# CH32F203xx register map
Vendor: WCH Ltd.; File version: 1.0
Registers are 32-bit, read-write, reset 0x0 unless marked. A register's access mark holds for its fields unless they carry their own. Offsets are from the block's base; [hi:lo] are bit positions; {n}, {i} and the like mark numbered series.

## AFIO — Alternate function I/O
Base 0x40010000
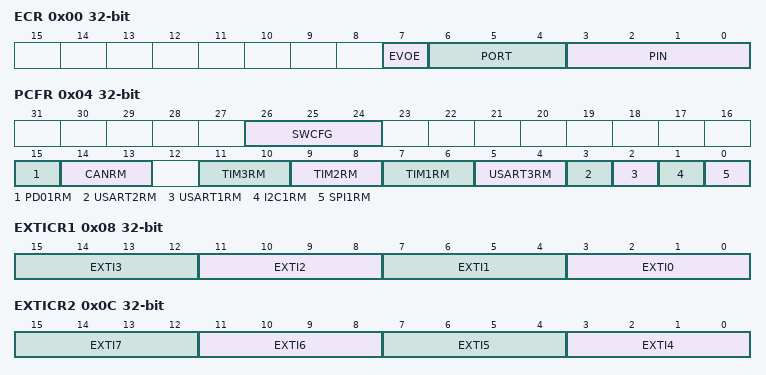
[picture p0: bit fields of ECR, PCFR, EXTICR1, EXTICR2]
0x00 ECR — Event Control Register (AFIO_ECR)
  [7] EVOE — Event Output Enable
  [6:4] PORT — Port selection
  [3:0] PIN — Pin selection
0x04 PCFR access per field — AF remap and debug I/O configuration register (AFIO_PCFR)
  [26:24] SWCFG wo — Serial wire JTAG configuration
  [15] PD01RM rw — Port D0/Port D1 mapping on OSCIN/OSCOUT
  [14:13] CANRM rw — CAN1 remapping
  [11:10] TIM3RM rw — TIM3 remapping
  [9:8] TIM2RM rw — TIM2 remapping
  [7:6] TIM1RM rw — TIM1 remapping
  [5:4] USART3RM rw — USART3 remapping
  [3] USART2RM rw — USART2 remapping
  [2] USART1RM rw — USART1 remapping
  [1] I2C1RM rw — I2C1 remapping
  [0] SPI1RM rw — SPI1 remapping
0x08 EXTICR1 — External interrupt configuration register 1 (AFIO_EXTICR1)
  [4n+3:4n] EXTI{n} (n=0..3) — EXTI{n} configuration
0x0C EXTICR2 — External interrupt configuration register 2 (AFIO_EXTICR2)
  [4n-13:4n-16] EXTI{n} (n=4..7) — EXTI{n} configuration
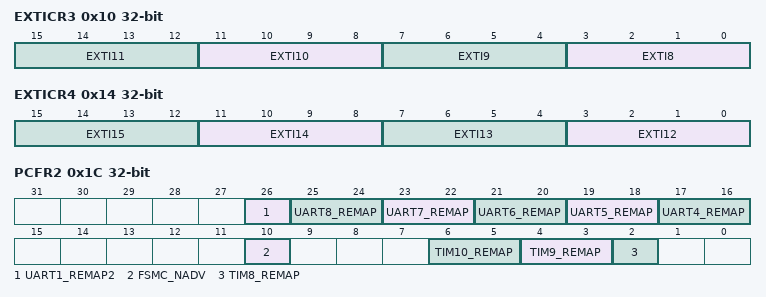
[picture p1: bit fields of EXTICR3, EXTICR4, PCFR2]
0x10 EXTICR3 — External interrupt configuration register 3 (AFIO_EXTICR3)
  [4n-29:4n-32] EXTI{n} (n=8..11) — EXTI{n} configuration
0x14 EXTICR4 — External interrupt configuration register 4 (AFIO_EXTICR4)
  [4n-45:4n-48] EXTI{n} (n=12..15) — EXTI{n} configuration
0x1C PCFR2 — AF remap and debug I/O configuration register (AFIO_PCFR2)
  [26] UART1_REMAP2 — UART1 remapping
  [2n+9:2n+8] UART{n}_REMAP (n=4..8) — UART{n} remapping
  [10] FSMC_NADV
  [6:5] TIM10_REMAP — TIM10 remapping
  [4:3] TIM9_REMAP — TIM9 remapping
  [2] TIM8_REMAP — TIM8 remapping

## EXTI
Base 0x40010400
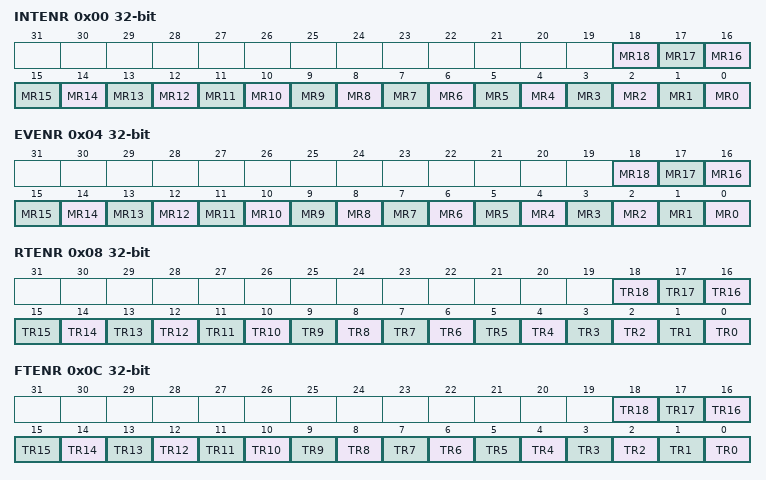
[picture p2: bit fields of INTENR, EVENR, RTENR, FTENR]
0x00 INTENR — Interrupt mask register (EXTI_INTENR)
  [n] MR{n} (n=0..18) — Interrupt Mask on line {n}
0x04 EVENR — Event mask register (EXTI_EVENR)
  [n] MR{n} (n=0..18) — Event Mask on line {n}
0x08 RTENR — Rising Trigger selection register (EXTI_RTENR)
  [n] TR{n} (n=0..18) — Rising trigger event configuration of line {n}
0x0C FTENR — Falling Trigger selection register (EXTI_FTENR)
  [n] TR{n} (n=0..18) — Falling trigger event configuration of line {n}
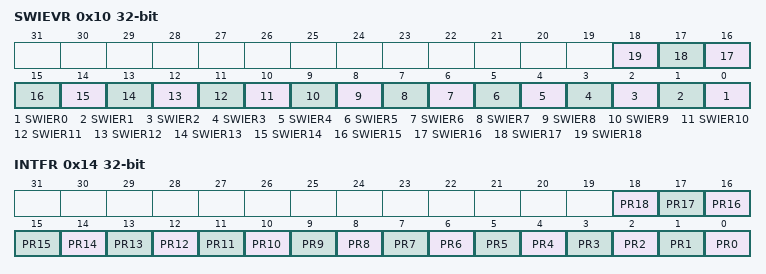
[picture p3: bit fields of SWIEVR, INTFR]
0x10 SWIEVR — Software interrupt event register (EXTI_SWIEVR)
  [n] SWIER{n} (n=0..18) — Software Interrupt on line {n}
0x14 INTFR — Pending register (EXTI_INTFR)
  [n] PR{n} (n=0..18) — Pending bit {n}

## RTC — Real time clock
Base 0x40002800
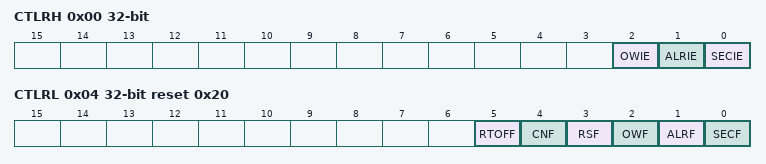
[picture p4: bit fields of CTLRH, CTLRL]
0x00 CTLRH — RTC Control Register High
  [2] OWIE — Overflow interrupt Enable
  [1] ALRIE — Alarm interrupt Enable
  [0] SECIE — Second interrupt Enable
0x04 CTLRL access per field reset 0x20 — RTC Control Register Low
  [5] RTOFF ro — RTC operation OFF
  [4] CNF rw — Configuration Flag
  [3] RSF rw — Registers Synchronized Flag
  [2] OWF rw — Overflow Flag
  [1] ALRF rw — Alarm Flag
  [0] SECF rw — Second Flag
0x08 PSCRH wo — RTC Prescaler Load Register High
  [3:0] PRLH
0x0C PSCRL wo reset 0x8000 — RTC Prescaler Load Register Low
  [15:0] PRLL — RTC Prescaler Divider Register Low
0x10 DIVH ro — RTC Prescaler Divider Register High
  [3:0] DIVH — RTC prescaler divider register high
0x14 DIVL ro reset 0x8000 — RTC Prescaler Divider Register Low
  [15:0] DIVL — RTC prescaler divider register Low
0x18 CNTH — RTC Counter Register High
  [15:0] CNTH — RTC counter register high
0x1C CNTL — RTC Counter Register Low
  [15:0] CNTL — RTC counter register Low
0x20 ALRMH wo reset 0xFFFF — RTC Alarm Register High
  [15:0] ALRH — RTC alarm register high
0x24 ALRML wo reset 0xFFFF — RTC Alarm Register Low
  [15:0] ALRL — RTC alarm register low

## BKP — Backup registers
Base 0x40006C00
0x00 DATAR1 — Backup data register (BKP_DR)
  [15:0] D1 — Backup data
0x04 DATAR2 — Backup data register (BKP_DR)
  [15:0] D2 — Backup data
0x08 DATAR3 — Backup data register (BKP_DR)
  [15:0] D3 — Backup data
0x0C DATAR4 — Backup data register (BKP_DR)
  [15:0] D4 — Backup data
0x10 DATAR5 — Backup data register (BKP_DR)
  [15:0] D5 — Backup data
0x14 DATAR6 — Backup data register (BKP_DR)
  [15:0] D6 — Backup data
0x18 DATAR7 — Backup data register (BKP_DR)
  [15:0] D7 — Backup data
0x1C DATAR8 — Backup data register (BKP_DR)
  [15:0] D8 — Backup data
0x20 DATAR9 — Backup data register (BKP_DR)
  [15:0] D9 — Backup data
0x24 DATAR10 — Backup data register (BKP_DR)
  [15:0] D10 — Backup data
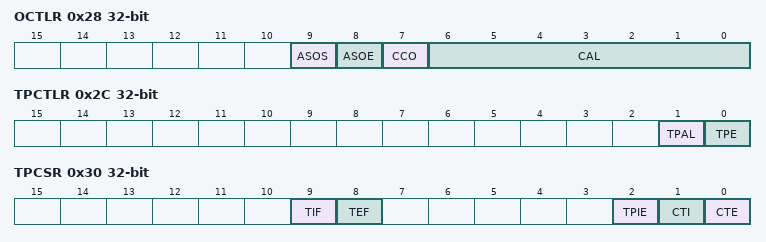
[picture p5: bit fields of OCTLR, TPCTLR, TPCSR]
0x28 OCTLR — RTC clock calibration register (BKP_OCTLR)
  [9] ASOS — Alarm or second output selection
  [8] ASOE — Alarm or second output enable
  [7] CCO — Calibration Clock Output
  [6:0] CAL — Calibration value
0x2C TPCTLR — Backup control register (BKP_TPCTLR)
  [1] TPAL — Tamper pin active level
  [0] TPE — Tamper pin enable
0x30 TPCSR access per field — BKP_TPCSR control/status register (BKP_CSR)
  [9] TIF ro — Tamper Interrupt Flag
  [8] TEF ro — Tamper Event Flag
  [2] TPIE rw — Tamper Pin interrupt enable
  [1] CTI wo — Clear Tamper Interrupt
  [0] CTE wo — Clear Tamper event
{0x10+4i} DATAR{i} (i=11..13) — Backup data register (BKP_DR)
  [15:0] DR{i} — Backup data
{0x10+4i} DATAR{i} (i=14..42) — Backup data register (BKP_DR)
  [15:0] D{i} — Backup data
